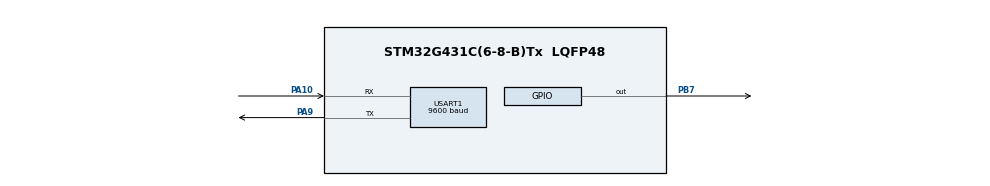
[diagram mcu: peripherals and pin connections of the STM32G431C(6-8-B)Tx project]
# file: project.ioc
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Mcu.Family=STM32G4
Mcu.Name=STM32G431C(6-8-B)Tx
Mcu.Package=LQFP48
NVIC.PriorityGroup=NVIC_PRIORITYGROUP_4
NVIC.TIM2_IRQn=true\:0\:0\:false\:false\:true\:true\:true\:true
NVIC.USART1_IRQn=true\:0\:0\:false\:false\:true\:true\:true\:true
PA10.Mode=Multiprocessor_communication
PA10.Signal=USART1_RX
PA13.Mode=Serial_Wire
PA13.Signal=SYS_JTMS-SWDIO
PA14.Mode=Serial_Wire
PA14.Signal=SYS_JTCK-SWCLK
PA9.Mode=Multiprocessor_communication
PA9.Signal=USART1_TX
PB7.GPIO_Speed=GPIO_SPEED_FREQ_HIGH
PB7.PinState=GPIO_PIN_RESET
PB7.Signal=GPIO_Output
PC14-OSC32_IN.Mode=LSE-External-Oscillator
PC14-OSC32_IN.Signal=RCC_OSC32_IN
PC15-OSC32_OUT.Mode=LSE-External-Oscillator
PC15-OSC32_OUT.Signal=RCC_OSC32_OUT
PF0-OSC_IN.Mode=HSE-External-Oscillator
PF0-OSC_IN.Signal=RCC_OSC_IN
PF1-OSC_OUT.Mode=HSE-External-Oscillator
PF1-OSC_OUT.Signal=RCC_OSC_OUT
ProjectManager.HeapSize=0x200
ProjectManager.StackSize=0x400
ProjectManager.TargetToolchain=MDK-ARM V5.32
RCC.ADC12Freq_Value=170000000
RCC.AHBFreq_Value=170000000
RCC.APB1Freq_Value=170000000
RCC.APB1TimFreq_Value=170000000
RCC.APB2Freq_Value=170000000
RCC.APB2TimFreq_Value=170000000
RCC.CortexFreq_Value=170000000
RCC.EXTERNAL_CLOCK_VALUE=12288000
RCC.HCLKFreq_Value=170000000
RCC.HSE_VALUE=25000000
RCC.HSI48_VALUE=48000000
RCC.HSI_VALUE=16000000
RCC.PLLM=RCC_PLLM_DIV5
RCC.PLLN=68
RCC.PLLSourceVirtual=RCC_PLLSOURCE_HSE
RCC.SYSCLKFreq_VALUE=170000000
RCC.SYSCLKSource=RCC_SYSCLKSOURCE_PLLCLK
RCC.USBFreq_Value=170000000
RCC.VCOOutputFreq_Value=340000000
TIM2.AutoReloadPreload=TIM_AUTORELOAD_PRELOAD_ENABLE
TIM2.PeriodNoDither=170*20-1
TIM2.Prescaler=1
USART1.BaudRate=9600
USART1.VirtualMode-Multiprocessor_communication=VM_ASYNC
VP_SYS_VS_DBSignals.Mode=DisableDeadBatterySignals
VP_TIM2_VS_ClockSourceINT.Mode=Internal
board=custom

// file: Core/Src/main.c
/* USER CODE BEGIN Header */
/**
  ******************************************************************************
  * @file           : main.c
  * @brief          : Main program body
  ******************************************************************************
  * @attention
  *
  * Copyright (c) 2025 STMicroelectronics.
  * All rights reserved.
  *
  * This software is licensed under terms that can be found in the LICENSE file
  * in the root directory of this software component.
  * If no LICENSE file comes with this software, it is provided AS-IS.
  *
  ******************************************************************************
  */
/* USER CODE END Header */
#include "main.h"
#include "tim.h"
#include "usart.h"
#include "gpio.h"

/* USER CODE BEGIN Includes */
#include "TFT_ILI9341.h"
#include "TFT_UI.h"
#include "UI_Ins_TestPage.h"
/* USER CODE END Includes */

void SystemClock_Config(void);

/* USER CODE BEGIN 0 */
extern uint8_t buff;
/* USER CODE END 0 */

int main(void)
{

  /* MCU Configuration--------------------------------------------------------*/

  /* Reset of all peripherals, Initializes the Flash interface and the Systick. */
  HAL_Init();

  /* Configure the system clock */
  SystemClock_Config();

  /* Initialize all configured peripherals */
  MX_GPIO_Init();
  MX_USART1_UART_Init();
  MX_TIM2_Init();
  /* USER CODE BEGIN 2 */
	//屏幕初始化
	Init_TFT();
	Init_UI();
	//串口调试
	HAL_UART_Receive_IT(&huart1,&buff,sizeof(buff));
	//40us中断
	__HAL_TIM_CLEAR_IT(&htim2,TIM_IT_UPDATE);
	HAL_TIM_Base_Start_IT(&htim2);

  /* USER CODE END 2 */

  /* Infinite loop */
  while (1)
  {

    /* USER CODE BEGIN 3 */
	  HAL_Delay(1);
	CircleRender_UI();

	TestPage_ClockCircle();
  }
  /* USER CODE END 3 */
}

void SystemClock_Config(void)
{
  LL_FLASH_SetLatency(LL_FLASH_LATENCY_4);
  while(LL_FLASH_GetLatency() != LL_FLASH_LATENCY_4)
  {
  }
  LL_PWR_EnableRange1BoostMode();
  LL_RCC_HSE_Enable();
   /* Wait till HSE is ready */
  while(LL_RCC_HSE_IsReady() != 1)
  {
  }

  LL_RCC_PLL_ConfigDomain_SYS(LL_RCC_PLLSOURCE_HSE, LL_RCC_PLLM_DIV_5, 68, LL_RCC_PLLR_DIV_2);
  LL_RCC_PLL_EnableDomain_SYS();
  LL_RCC_PLL_Enable();
   /* Wait till PLL is ready */
  while(LL_RCC_PLL_IsReady() != 1)
  {
  }

  LL_RCC_SetSysClkSource(LL_RCC_SYS_CLKSOURCE_PLL);
  LL_RCC_SetAHBPrescaler(LL_RCC_SYSCLK_DIV_2);
   /* Wait till System clock is ready */
  while(LL_RCC_GetSysClkSource() != LL_RCC_SYS_CLKSOURCE_STATUS_PLL)
  {
  }

  /* Insure 1us transition state at intermediate medium speed clock*/
  for (__IO uint32_t i = (170 >> 1); i !=0; i--);

  /* Set AHB prescaler*/
  LL_RCC_SetAHBPrescaler(LL_RCC_SYSCLK_DIV_1);
  LL_RCC_SetAPB1Prescaler(LL_RCC_APB1_DIV_1);
  LL_RCC_SetAPB2Prescaler(LL_RCC_APB2_DIV_1);
  LL_SetSystemCoreClock(170000000);

   /* Update the time base */
  if (HAL_InitTick (TICK_INT_PRIORITY) != HAL_OK)
  {
    Error_Handler();
  }
}

void Error_Handler(void)
{
  __disable_irq();
  while (1)
  {
  }
}
